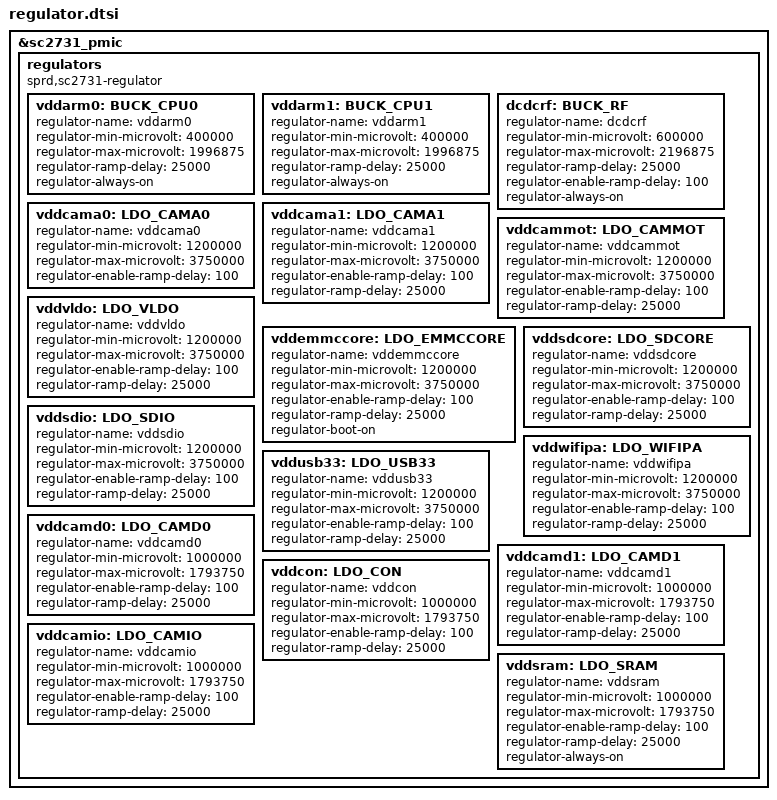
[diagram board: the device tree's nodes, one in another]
&sc2731_pmic {
	regulators {
		compatible = "sprd,sc2731-regulator";
		/* regulator-debugfs-enable; */

		vddarm0: BUCK_CPU0 {
			regulator-name = "vddarm0";
			regulator-min-microvolt = <400000>;
			regulator-max-microvolt = <1996875>;
			regulator-ramp-delay = <25000>;
			regulator-always-on;
		};

		vddarm1: BUCK_CPU1 {
			regulator-name = "vddarm1";
			regulator-min-microvolt = <400000>;
			regulator-max-microvolt = <1996875>;
			regulator-ramp-delay = <25000>;
			regulator-always-on;
		};

		dcdcrf: BUCK_RF {
			regulator-name = "dcdcrf";
			regulator-min-microvolt = <600000>;
			regulator-max-microvolt = <2196875>;
			regulator-ramp-delay = <25000>;
			regulator-enable-ramp-delay = <100>;
			regulator-always-on;
		};

		vddcama0: LDO_CAMA0 {
			regulator-name = "vddcama0";
			regulator-min-microvolt = <1200000>;
			regulator-max-microvolt = <3750000>;
			regulator-enable-ramp-delay = <100>;
		};

		vddcama1: LDO_CAMA1 {
			regulator-name = "vddcama1";
			regulator-min-microvolt = <1200000>;
			regulator-max-microvolt = <3750000>;
			regulator-enable-ramp-delay = <100>;
			regulator-ramp-delay = <25000>;
		};

		vddcammot: LDO_CAMMOT {
			regulator-name = "vddcammot";
			regulator-min-microvolt = <1200000>;
			regulator-max-microvolt = <3750000>;
			regulator-enable-ramp-delay = <100>;
			regulator-ramp-delay = <25000>;
		};

		vddvldo: LDO_VLDO {
			regulator-name = "vddvldo";
			regulator-min-microvolt = <1200000>;
			regulator-max-microvolt = <3750000>;
			regulator-enable-ramp-delay = <100>;
			regulator-ramp-delay = <25000>;
		};

		vddemmccore: LDO_EMMCCORE {
			regulator-name = "vddemmccore";
			regulator-min-microvolt = <1200000>;
			regulator-max-microvolt = <3750000>;
			regulator-enable-ramp-delay = <100>;
			regulator-ramp-delay = <25000>;
			regulator-boot-on;
		};

		vddsdcore: LDO_SDCORE {
			regulator-name = "vddsdcore";
			regulator-min-microvolt = <1200000>;
			regulator-max-microvolt = <3750000>;
			regulator-enable-ramp-delay = <100>;
			regulator-ramp-delay = <25000>;
		};

		vddsdio: LDO_SDIO {
			regulator-name = "vddsdio";
			regulator-min-microvolt = <1200000>;
			regulator-max-microvolt = <3750000>;
			regulator-enable-ramp-delay = <100>;
			regulator-ramp-delay = <25000>;
		};

		vddwifipa: LDO_WIFIPA {
			regulator-name = "vddwifipa";
			regulator-min-microvolt = <1200000>;
			regulator-max-microvolt = <3750000>;
			regulator-enable-ramp-delay = <100>;
			regulator-ramp-delay = <25000>;
		};

		vddusb33: LDO_USB33 {
			regulator-name = "vddusb33";
			regulator-min-microvolt = <1200000>;
			regulator-max-microvolt = <3750000>;
			regulator-enable-ramp-delay = <100>;
			regulator-ramp-delay = <25000>;
		};

		vddcamd0: LDO_CAMD0 {
			regulator-name = "vddcamd0";
			regulator-min-microvolt = <1000000>;
			regulator-max-microvolt = <1793750>;
			regulator-enable-ramp-delay = <100>;
			regulator-ramp-delay = <25000>;
		};

		vddcamd1: LDO_CAMD1 {
			regulator-name = "vddcamd1";
			regulator-min-microvolt = <1000000>;
			regulator-max-microvolt = <1793750>;
			regulator-enable-ramp-delay = <100>;
			regulator-ramp-delay = <25000>;
		};

		vddcon: LDO_CON {
			regulator-name = "vddcon";
			regulator-min-microvolt = <1000000>;
			regulator-max-microvolt = <1793750>;
			regulator-enable-ramp-delay = <100>;
			regulator-ramp-delay = <25000>;
		};

		vddcamio: LDO_CAMIO {
			regulator-name = "vddcamio";
			regulator-min-microvolt = <1000000>;
			regulator-max-microvolt = <1793750>;
			regulator-enable-ramp-delay = <100>;
			regulator-ramp-delay = <25000>;
		};

		vddsram: LDO_SRAM {
			regulator-name = "vddsram";
			regulator-min-microvolt = <1000000>;
			regulator-max-microvolt = <1793750>;
			regulator-enable-ramp-delay = <100>;
			regulator-ramp-delay = <25000>;
			regulator-always-on;
		};
	};
};
